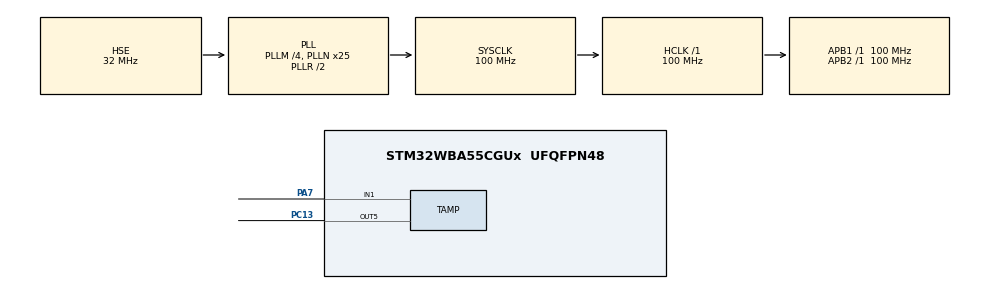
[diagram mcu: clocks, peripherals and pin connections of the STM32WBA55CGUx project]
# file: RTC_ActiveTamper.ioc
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CORTEX_M33_NS.userName=CORTEX_M33
Mcu.Family=STM32WBA
Mcu.Name=STM32WBA55CGUx
Mcu.Package=UFQFPN48
NVIC.PriorityGroup=NVIC_PRIORITYGROUP_4
NVIC.TAMP_IRQn=true\:0\:0\:false\:false\:true\:true\:true\:true
OSC_IN.Mode=HSE-External-Oscillator
OSC_IN.Signal=RCC_OSC_IN
OSC_OUT.Mode=HSE-External-Oscillator
OSC_OUT.Signal=RCC_OSC_OUT
PA7.Mode=Tamper_1_enabled
PA7.Signal=TAMP_IN1
PC13.Mode=Tamper 5 OUT enabled
PC13.Signal=TAMP_OUT5
PC14-OSC32_IN.Mode=LSE-External-Oscillator-for-RTC
PC14-OSC32_IN.Signal=RCC_OSC32_IN
PC15-OSC32_OUT.Mode=LSE-External-Oscillator-for-RTC
PC15-OSC32_OUT.Signal=RCC_OSC32_OUT
ProjectManager.HeapSize=0x200
ProjectManager.StackSize=0x400
ProjectManager.TargetToolchain=EWARM V9.20
RCC.ADCFreq_Value=100000000
RCC.AHB5CLKDivider=DIV4
RCC.AHBFreq_Value=100000000
RCC.APB1Freq_Value=100000000
RCC.APB1TimFreq_Value=100000000
RCC.APB2Freq_Value=100000000
RCC.APB2TimFreq_Value=100000000
RCC.CortexFreq_Value=12500000
RCC.HCLKFreq_Value=100000000
RCC.HSE_VALUE=32000000
RCC.HSI_VALUE=16000000
RCC.LSI1_VALUE=32000
RCC.LSI2_VALUE=32000
RCC.PLLFRACN=0
RCC.PLLM=4
RCC.PLLN=25
RCC.PLLSourceVirtual=RCC_PLLSOURCE_HSE
RCC.RTCClockSelection=RCC_RTCCLKSOURCE_LSE
RCC.SYSCLKFreq_VALUE=100000000
RCC.SYSCLKSourceVirtual=RCC_SYSCLKSOURCE_PLLCLK
RCC.VCOOutputFreq_Value=200000000
TAMP.Interrupt1=RTC_ATAMP_INTERRUPT_ENABLE
VP_CORTEX_M33_NS_VS_Hclk.Mode=Hclk_Mode
VP_ICACHE_VS_ICACHE.Mode=DirectMappedCache
VP_MEMORYMAP_VS_MEMORYMAP.Mode=CurAppReg
VP_PWR_VS_SECSignals.Mode=Security/Privilege
VP_RTC_VS_RTC_Activate.Mode=RTC_Enabled
board=custom

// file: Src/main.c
/* USER CODE BEGIN Header */
/**
  ******************************************************************************
  * @file    RTC/RTC_ActiveTamper/Src/main.c
  * @author  MCD Application Team
  * @brief   This sample code shows how to use STM32WBAxx RTC HAL API to write/read
  *          data to/from RTC Backup data registers and demonstrates the Active Tamper
  *          detection feature.
  ******************************************************************************
  * @attention
  *
  * Copyright (c) 2023 STMicroelectronics.
  * All rights reserved.
  *
  * This software is licensed under terms that can be found in the LICENSE file
  * in the root directory of this software component.
  * If no LICENSE file comes with this software, it is provided AS-IS.
  *
  ******************************************************************************
  */
/* USER CODE END Header */
#include "main.h"

RTC_HandleTypeDef hrtc;

/* USER CODE BEGIN PV */
__IO FlagStatus TamperStatus;

/* USER CODE END PV */

void SystemClock_Config(void);
static void MX_GPIO_Init(void);
static void MX_RTC_Init(void);
static void MX_TAMP_RTC_Init(void);
static void MX_ICACHE_Init(void);

int main(void)
{

  /* USER CODE BEGIN 1 */
  uint32_t Seed[4] = {0xFEFEFEFEu, 0xAAAAAAAAu, 0x0u, 0xFFFF0000u};
  uint32_t i;

  /* STM32WBAxx HAL library initialization:
       - Systick timer is configured by default as source of time base, but user
             can eventually implement his proper time base source (a general purpose
             timer for example or other time source), keeping in mind that Time base
             duration should be kept 1ms since PPP_TIMEOUT_VALUEs are defined and
             handled in milliseconds basis.
       - Set NVIC Group Priority to 4
       - Low Level Initialization
     */

  /* USER CODE END 1 */

  /* MCU Configuration--------------------------------------------------------*/

  /* Reset of all peripherals, Initializes the Flash interface and the Systick. */
  HAL_Init();

  /* USER CODE BEGIN Init */
  /* Configure LD3 */
  BSP_LED_Init(LD3);

  /* USER CODE END Init */

  /* Configure the system clock */
  SystemClock_Config();

  /* Initialize all configured peripherals */
  MX_GPIO_Init();
  MX_RTC_Init();
  MX_TAMP_RTC_Init();
  MX_ICACHE_Init();
  /* USER CODE BEGIN 2 */

  /* Check if Tamper is not detected */
  for (i = 0; i < RTC_BKP_NUMBER; i++)
  {
    if (HAL_RTCEx_BKUPRead(&hrtc, i) == 0x0u)
    {
      /* Please verify that All Tampers In and the Tamper Out are linked together */
      Error_Handler();
    }
  }

  /* Update the seed with "random" values */
  for (i = 0; i < 5; i++)
  {
    Seed[0] -= 0xFEFEFEu * i;
    Seed[1] += 0xAAAu;
    Seed[2] += Seed[0] - Seed[1];
    Seed[3] += 4 * Seed[0] + 0x123456u;

    if (HAL_RTCEx_SetActiveSeed(&hrtc, Seed) != HAL_OK)
    {
      Error_Handler();
    }

    HAL_Delay(100);
  }

  /* Check if Tamper is not detected */
  for (i = 0; i < RTC_BKP_NUMBER; i++)
  {
    if (HAL_RTCEx_BKUPRead(&hrtc, i) == 0)
    {
       Error_Handler();
    }
  }
  /* Clear tamper interrupt flag */
  TamperStatus = RESET;

  /* Wait for tamper detection. User must disconnect the wire */
  while (TamperStatus == RESET);

  /* Disable Active Tampers */
  if (HAL_RTCEx_DeactivateActiveTampers(&hrtc) != HAL_OK)
  {
    Error_Handler();
  }

  /* Check that Backup registers have been cleared by the tamper detection */
  for (i = 0; i < RTC_BKP_NUMBER; i++)
  {
    if (HAL_RTCEx_BKUPRead(&hrtc, i) != 0)
    {
      Error_Handler();
    }
  }

  /* Test is OK Turn on LD3 */
  BSP_LED_On(LD3);

  /* USER CODE END 2 */

  /* Infinite loop */
  while (1)
  {

  }
}

void SystemClock_Config(void)
{
  RCC_OscInitTypeDef RCC_OscInitStruct = {0};
  RCC_ClkInitTypeDef RCC_ClkInitStruct = {0};

  /** Supply configuration update enable
  */
  HAL_PWREx_ConfigSupply(PWR_LDO_SUPPLY);

  /** Configure the main internal regulator output voltage
  */
  if (HAL_PWREx_ControlVoltageScaling(PWR_REGULATOR_VOLTAGE_SCALE1) != HAL_OK)
  {
    Error_Handler();
  }

  /** Configure LSE Drive Capability
  */
  HAL_PWR_EnableBkUpAccess();
  __HAL_RCC_LSEDRIVE_CONFIG(RCC_LSEDRIVE_MEDIUMLOW);

  /** Initializes the CPU, AHB and APB busses clocks
  */
  RCC_OscInitStruct.OscillatorType = RCC_OSCILLATORTYPE_HSE|RCC_OSCILLATORTYPE_LSE;
  RCC_OscInitStruct.HSEState = RCC_HSE_ON;
  RCC_OscInitStruct.HSEDiv = RCC_HSE_DIV1;
  RCC_OscInitStruct.LSEState = RCC_LSE_ON_RTC_ONLY;
  RCC_OscInitStruct.PLL1.PLLState = RCC_PLL_ON;
  RCC_OscInitStruct.PLL1.PLLSource = RCC_PLLSOURCE_HSE;
  RCC_OscInitStruct.PLL1.PLLM = 4;
  RCC_OscInitStruct.PLL1.PLLN = 25;
  RCC_OscInitStruct.PLL1.PLLP = 2;
  RCC_OscInitStruct.PLL1.PLLQ = 2;
  RCC_OscInitStruct.PLL1.PLLR = 2;
  RCC_OscInitStruct.PLL1.PLLFractional = 0;
  if (HAL_RCC_OscConfig(&RCC_OscInitStruct) != HAL_OK)
  {
    Error_Handler();
  }

  /** Initializes the CPU, AHB and APB busses clocks
  */
  RCC_ClkInitStruct.ClockType = RCC_CLOCKTYPE_HCLK|RCC_CLOCKTYPE_SYSCLK
                              |RCC_CLOCKTYPE_PCLK1|RCC_CLOCKTYPE_PCLK2
                              |RCC_CLOCKTYPE_PCLK7|RCC_CLOCKTYPE_HCLK5;
  RCC_ClkInitStruct.SYSCLKSource = RCC_SYSCLKSOURCE_PLLCLK;
  RCC_ClkInitStruct.AHBCLKDivider = RCC_SYSCLK_DIV1;
  RCC_ClkInitStruct.APB1CLKDivider = RCC_HCLK_DIV1;
  RCC_ClkInitStruct.APB2CLKDivider = RCC_HCLK_DIV1;
  RCC_ClkInitStruct.APB7CLKDivider = RCC_HCLK_DIV1;
  RCC_ClkInitStruct.AHB5_PLL1_CLKDivider = RCC_SYSCLK_PLL1_DIV4;
  RCC_ClkInitStruct.AHB5_HSEHSI_CLKDivider = RCC_SYSCLK_HSEHSI_DIV1;

  if (HAL_RCC_ClockConfig(&RCC_ClkInitStruct, FLASH_LATENCY_3) != HAL_OK)
  {
    Error_Handler();
  }
}

static void MX_ICACHE_Init(void)
{

  /** Enable instruction cache in 1-way (direct mapped cache)
  */
  if (HAL_ICACHE_ConfigAssociativityMode(ICACHE_1WAY) != HAL_OK)
  {
    Error_Handler();
  }
  if (HAL_ICACHE_Enable() != HAL_OK)
  {
    Error_Handler();
  }

}

static void MX_RTC_Init(void)
{

  RTC_PrivilegeStateTypeDef privilegeState = {0};

  /* USER CODE BEGIN RTC_Init 1 */

  /* Use __HAL_DBGMCU_FREEZE_RTC(); to freeze the RTC during debug */

  /* USER CODE END RTC_Init 1 */

  /** Initialize RTC Only
  */
  hrtc.Instance = RTC;
  hrtc.Init.HourFormat = RTC_HOURFORMAT_24;
  hrtc.Init.AsynchPrediv = 127;
  hrtc.Init.SynchPrediv = 255;
  hrtc.Init.OutPut = RTC_OUTPUT_DISABLE;
  hrtc.Init.OutPutRemap = RTC_OUTPUT_REMAP_NONE;
  hrtc.Init.OutPutPolarity = RTC_OUTPUT_POLARITY_HIGH;
  hrtc.Init.OutPutType = RTC_OUTPUT_TYPE_OPENDRAIN;
  hrtc.Init.OutPutPullUp = RTC_OUTPUT_PULLUP_NONE;
  hrtc.Init.BinMode = RTC_BINARY_NONE;
  if (HAL_RTC_Init(&hrtc) != HAL_OK)
  {
    Error_Handler();
  }
  privilegeState.rtcPrivilegeFull = RTC_PRIVILEGE_FULL_NO;
  privilegeState.backupRegisterPrivZone = RTC_PRIVILEGE_BKUP_ZONE_NONE;
  privilegeState.backupRegisterStartZone2 = RTC_BKP_DR0;
  privilegeState.backupRegisterStartZone3 = RTC_BKP_DR0;
  if (HAL_RTCEx_PrivilegeModeSet(&hrtc, &privilegeState) != HAL_OK)
  {
    Error_Handler();
  }
  /* USER CODE BEGIN RTC_Init 2 */

  /* Calendar ultra-low power mode */
  if (HAL_RTCEx_SetLowPowerCalib(&hrtc, RTC_LPCAL_SET) != HAL_OK)
  {
    Error_Handler();
  }

  /* Set all backup registers to 0xFFFFFFFF.
     Backup registers will be cleared by a tamper detection. */
  for (uint32_t i = 0; i < RTC_BKP_NUMBER; i++)
  {
    HAL_RTCEx_BKUPWrite(&hrtc, i, 0xFFFFFFFF);
  }
  /* USER CODE END RTC_Init 2 */

}

static void MX_TAMP_RTC_Init(void)
{

  RTC_PrivilegeStateTypeDef privilegeState = {0};
  RTC_ActiveTampersTypeDef sAllTamper = {0};

  /** Enable the RTC Active Tamper
  */
  privilegeState.tampPrivilegeFull = TAMP_PRIVILEGE_FULL_YES;
  if (HAL_RTCEx_PrivilegeModeSet(&hrtc, &privilegeState) != HAL_OK)
  {
    Error_Handler();
  }
  sAllTamper.ActiveFilter = RTC_ATAMP_FILTER_DISABLE;
  sAllTamper.ActiveAsyncPrescaler = RTC_ATAMP_ASYNCPRES_RTCCLK;
  sAllTamper.TimeStampOnTamperDetection = RTC_TIMESTAMPONTAMPERDETECTION_ENABLE;
  sAllTamper.ActiveOutputChangePeriod = 0;
  sAllTamper.Seed[0] = 0x00000000;
  sAllTamper.Seed[1] = 0x00000000;
  sAllTamper.Seed[2] = 0x00000000;
  sAllTamper.Seed[3] = 0x00000000;
  sAllTamper.TampInput[RTC_ATAMP_1].Enable = RTC_ATAMP_ENABLE;
  sAllTamper.TampInput[RTC_ATAMP_1].Interrupt = RTC_ATAMP_INTERRUPT_ENABLE;
  sAllTamper.TampInput[RTC_ATAMP_1].Output = RTC_ATAMP_5;
  sAllTamper.TampInput[RTC_ATAMP_1].NoErase = RTC_TAMPER_ERASE_BACKUP_ENABLE;
  sAllTamper.TampInput[RTC_ATAMP_1].MaskFlag = RTC_TAMPERMASK_FLAG_DISABLE;
  if (HAL_RTCEx_SetActiveTampers(&hrtc, &sAllTamper) != HAL_OK)
  {
    Error_Handler();
  }

}

static void MX_GPIO_Init(void)
{

  /* GPIO Ports Clock Enable */
  __HAL_RCC_GPIOA_CLK_ENABLE();
  __HAL_RCC_GPIOC_CLK_ENABLE();

}

/* USER CODE BEGIN 4 */
/**
  * @brief  Tamper event callback function
  * @param  RTC handle
  * @retval None
  */
void HAL_RTCEx_Tamper1EventCallback(RTC_HandleTypeDef *hrtc)
{
  TamperStatus = SET;
}

/* USER CODE END 4 */

void Error_Handler(void)
{
  /* USER CODE BEGIN Error_Handler_Debug */
  while (1)
  {
    BSP_LED_Toggle(LD3);
    HAL_Delay(100);
  }
  /* USER CODE END Error_Handler_Debug */
}
